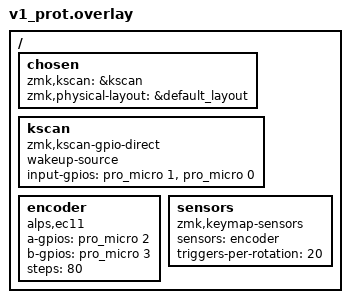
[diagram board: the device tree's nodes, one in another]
// This file was generated from a template. Edit it to match your keyboard.
// See https://zmk.dev/docs/development/hardware-integration/new-shield for more
// instructions.


/ {
    chosen {
        zmk,kscan = &kscan;
        zmk,physical-layout = &default_layout;
    };

    kscan: kscan {
        compatible = "zmk,kscan-gpio-direct";
        wakeup-source;

        input-gpios
            = <&pro_micro 1 GPIO_ACTIVE_HIGH>
            , <&pro_micro 0 GPIO_ACTIVE_HIGH>
            ;

    };

    encoder: encoder {
        compatible = "alps,ec11";
        a-gpios = <&pro_micro 2 (GPIO_ACTIVE_HIGH | GPIO_PULL_UP)>;
        b-gpios = <&pro_micro 3 (GPIO_ACTIVE_HIGH | GPIO_PULL_UP)>;
        status = "okay";
        steps = <80>;
    };

    sensors: sensors {
        compatible = "zmk,keymap-sensors";
        sensors = <&encoder>;
        triggers-per-rotation = <20>;
    };

};
